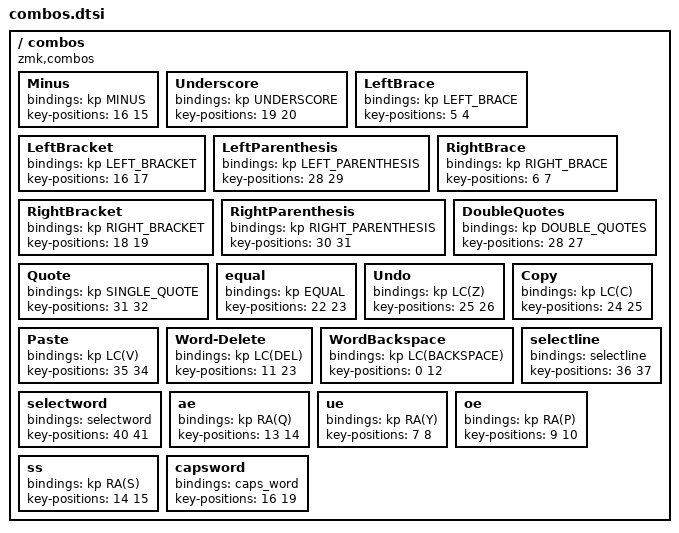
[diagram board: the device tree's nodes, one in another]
/ combos {
        compatible = "zmk,combos";

        Minus {
            bindings = <&kp MINUS>;
            key-positions = <16 15>;
        };

        Underscore {
            bindings = <&kp UNDERSCORE>;
            key-positions = <19 20>;
        };

        LeftBrace {
            bindings = <&kp LEFT_BRACE>;
            key-positions = <5 4>;
        };

        LeftBracket {
            bindings = <&kp LEFT_BRACKET>;
            key-positions = <16 17>;
        };

        LeftParenthesis {
            bindings = <&kp LEFT_PARENTHESIS>;
            key-positions = <28 29>;
        };

        RightBrace {
            bindings = <&kp RIGHT_BRACE>;
            key-positions = <6 7>;
        };

        RightBracket {
            bindings = <&kp RIGHT_BRACKET>;
            key-positions = <18 19>;
        };

        RightParenthesis {
            bindings = <&kp RIGHT_PARENTHESIS>;
            key-positions = <30 31>;
        };

        DoubleQuotes {
            bindings = <&kp DOUBLE_QUOTES>;
            key-positions = <28 27>;
        };

        Quote {
            bindings = <&kp SINGLE_QUOTE>;
            key-positions = <31 32>;
        };

        equal {
            bindings = <&kp EQUAL>;
            key-positions = <22 23>;
        };

        Undo {
            bindings = <&kp LC(Z)>;
            key-positions = <25 26>;
        };

        Copy {
            bindings = <&kp LC(C)>;
            key-positions = <24 25>;
        };

        Paste {
            bindings = <&kp LC(V)>;
            key-positions = <35 34>;
        };

        Word-Delete {
            bindings = <&kp LC(DEL)>;
            key-positions = <11 23>;
        };

        WordBackspace {
            bindings = <&kp LC(BACKSPACE)>;
            key-positions = <0 12>;
        };

        selectline {
            bindings = <&selectline>;
            key-positions = <36 37>;
        };

        selectword {
            bindings = <&selectword>;
            key-positions = <40 41>;
        };

        ae {
            bindings = <&kp RA(Q)>;
            key-positions = <13 14>;
        };

        ue {
            bindings = <&kp RA(Y)>;
            key-positions = <7 8>;
        };

        oe {
            bindings = <&kp RA(P)>;
            key-positions = <9 10>;
        };

        ss {
            bindings = <&kp RA(S)>;
            key-positions = <14 15>;
        };

        capsword {
            bindings = <&caps_word>;
            key-positions = <16 19>;
        };
    };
